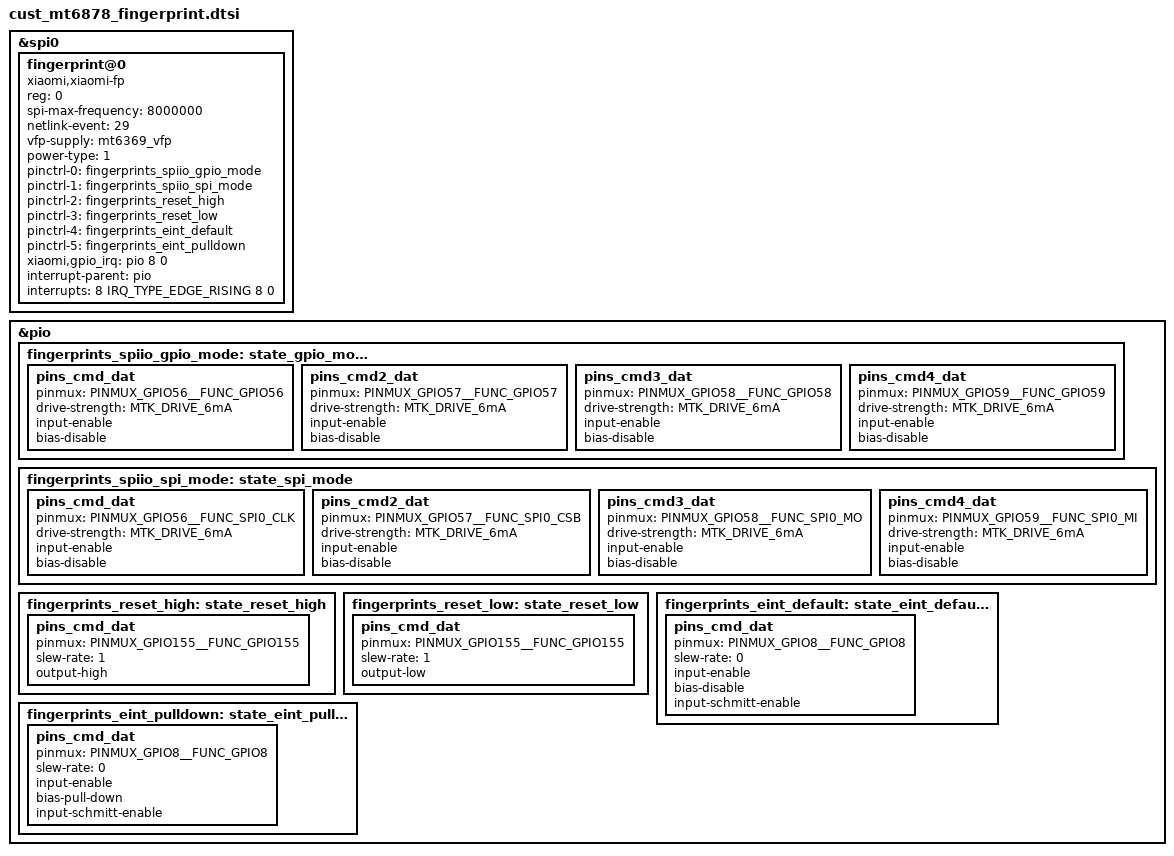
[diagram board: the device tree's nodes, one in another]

// SPDX-License-Identifier: (GPL-2.0 OR MIT)
/*
 * Copyright (C) 2023 MediaTek Inc.
 */
/* fingerprint start */
&spi0 {
	#address-cells = <1>;
	#size-cells = <0>;
	fingerprint@0 {
		compatible = "xiaomi,xiaomi-fp";
		reg = <0>;
		spi-max-frequency = <8000000>;
		netlink-event = <29>;
		vfp-supply = <&mt6369_vfp>;
		power-type = <1>;
		pinctrl-names = "spiio_gpio_mode", "spiio_spi_mode", "reset_high", "reset_low", "eint_default", "eint_pulldown";
		pinctrl-0 = <&fingerprints_spiio_gpio_mode>;
		pinctrl-1 = <&fingerprints_spiio_spi_mode>;
		pinctrl-2 = <&fingerprints_reset_high>;
		pinctrl-3 = <&fingerprints_reset_low>;
		pinctrl-4 = <&fingerprints_eint_default>;
		pinctrl-5 = <&fingerprints_eint_pulldown>;
		xiaomi,gpio_irq = <&pio 8 0>;
		interrupt-parent = <&pio>;
		interrupts = <8 IRQ_TYPE_EDGE_RISING 8 0>;
		status = "okay";
	};
};
&pio {
	fingerprints_spiio_gpio_mode: state_gpio_mode {
		pins_cmd_dat {
			pinmux = <PINMUX_GPIO56__FUNC_GPIO56>;
			drive-strength = <MTK_DRIVE_6mA>;
			input-enable;
			bias-disable;
		};
		pins_cmd2_dat {
			pinmux = <PINMUX_GPIO57__FUNC_GPIO57>;
			drive-strength = <MTK_DRIVE_6mA>;
			input-enable;
			bias-disable;
		};
		pins_cmd3_dat {
			pinmux = <PINMUX_GPIO58__FUNC_GPIO58>;
			drive-strength = <MTK_DRIVE_6mA>;
			input-enable;
			bias-disable;
		};
		pins_cmd4_dat {
			pinmux = <PINMUX_GPIO59__FUNC_GPIO59>;
			drive-strength = <MTK_DRIVE_6mA>;
			input-enable;
			bias-disable;
		};
	};
	fingerprints_spiio_spi_mode: state_spi_mode {
		pins_cmd_dat {
			pinmux = <PINMUX_GPIO56__FUNC_SPI0_CLK>;
			drive-strength = <MTK_DRIVE_6mA>;
			input-enable;
			bias-disable;
		};
		pins_cmd2_dat {
			pinmux = <PINMUX_GPIO57__FUNC_SPI0_CSB>;
			drive-strength = <MTK_DRIVE_6mA>;
			input-enable;
			bias-disable;
		};
		pins_cmd3_dat {
			pinmux = <PINMUX_GPIO58__FUNC_SPI0_MO>;
			drive-strength = <MTK_DRIVE_6mA>;
			input-enable;
			bias-disable;
		};
		pins_cmd4_dat {
			pinmux = <PINMUX_GPIO59__FUNC_SPI0_MI>;
			drive-strength = <MTK_DRIVE_6mA>;
			input-enable;
			bias-disable;
		};
	};
	fingerprints_reset_high: state_reset_high {
		pins_cmd_dat {
			pinmux = <PINMUX_GPIO155__FUNC_GPIO155>;
			slew-rate = <1>;
			output-high;
		};
	};
	fingerprints_reset_low: state_reset_low {
		pins_cmd_dat {
			pinmux = <PINMUX_GPIO155__FUNC_GPIO155>;
			slew-rate = <1>;
			output-low;
		};
	};
	fingerprints_eint_default: state_eint_default {
		pins_cmd_dat {
			pinmux = <PINMUX_GPIO8__FUNC_GPIO8>;
			slew-rate = <0>;
			input-enable;
			bias-disable;
			input-schmitt-enable;
		};
	};
	fingerprints_eint_pulldown: state_eint_pulldown {
		pins_cmd_dat {
			pinmux = <PINMUX_GPIO8__FUNC_GPIO8>;
			slew-rate = <0>;
			input-enable;
			bias-pull-down;
			input-schmitt-enable;
		};
	};
};
/* fingerprint end */

